# RL6845_IP_SVD register map
Vendor: Realtek
IP svd file
Registers are 32-bit, read-write, reset 0x0 unless marked. A register's access mark holds for its fields unless they carry their own. Offsets are from the block's base; lines under a group give offsets from that group; [hi:lo] are bit positions; {n}, {i} and the like mark numbered series; 'fields as' and 'values as' point back to an identical list; <NAME> marks a mode.

## Memory map
0x40000000 PAGE0 size 0x100
0x40000000 PAGE1 size 0x1200
0x40000000 PAGE2 size 0x300
0x40000000 PAGE3 size 0x1314
0x40000000 PAGE4 size 0x1488
0x40000000 PAGE5 size 0x15A4
0x40000000 PAGE6 size 0x1700
0x40000000 PAGE7 size 0x800
0x40100000 AES_REG size 0x101C
0x40108000 SHA_REG size 0x101C
0x40110000 GDMA0_REG size 0x400
0x40124000 SPI0_REG size 0xB0C
0x40125000 SPI1_REG size 0xB0C
0x40126000 PSRAM_PHY_REG size 0xFC
0x40127000 PSRAM_REG size 0x1D4
0x40128000 SPI_FLASH_CTRL size 0x1D4
0x40129000 QSPI_REG size 0x1D4
0x4012A000 SPORT0_REG size 0x984
0x4012B000 SPORT1_REG size 0x984
0x41000000 OTPC_REG size 0x744
0x41008000 LP_AON size 0x100
0x41008100 LDO size 0x80
0x41008180 SWR size 0x80
0x41008200 LP_SYS size 0x100
0x41008300 PMC size 0x88
0x41008400 XTAL size 0x3C
0x41008440 PLL size 0x40
0x41008480 WLAFE size 0x40
0x41008600 MEMX size 0x200
0x41008800 PINMUX_REG size 0x200
0x41008A00 RTC size 0x2C
0x41008C00 IWDG_REG size 0x14
0x41008D00 WDG0_REG size 0x14
0x41008D80 WDG2_REG size 0x14
0x41009000 SDM_REG size 0x24
0x4100C000 UART0_REG size 0x64
0x4100D000 UART1_REG size 0x64
0x4100E000 UART2_REG size 0x64
0x4100F000 UARTLOG_REG size 0xF4
0x41010000 GPIO_REG size 0x100
0x41011000 ADC_REG size 0xBC
0x41011800 CMP_REG size 0x58
0x41012000 CTC_REG size 0x214
0x41013000 KSCAN_REG size 0x5C
0x41014000 IPC0_REG size 0x1C
0x41014080 IPC1_REG size 0x1C
0x41015000 DEBUGTIMER_REG size 0x18
0x41016000 PMC_TIMER_REG size 0x34
{0x41017000+0x200*n} TIMER{n}_REG size 0x88 (n=0..7)
0x41100000 TIMER8_REG size 0x88
0x41100200 TIMER9_REG size 0x88
0x41100400 TIMER10_REG size 0x88
0x41100600 TIMER11_REG size 0x88
0x41101000 TRNG_REG size 0x200
0x41102000 RXI300_REG size 0x1140
0x41104000 RSIP_REG size 0x300
0x41105000 LEDC_REG size 0xF8
0x41106000 AUDIO_REG size 0x82C
0x41107000 IR_REG size 0x34
0x41108000 I2C0_REG size 0x104
0x4110A000 I2C1_REG size 0x104
0x51008D40 WDG1_REG_S size 0x14
0x51102200 MPC1_S size 0x1140
0x51102300 MPC2_S size 0x1140
0x51102400 PPC_S size 0x1140

## IPC0_REG
Base 0x41014000
Same registers: IPC1_REG 0x41014080
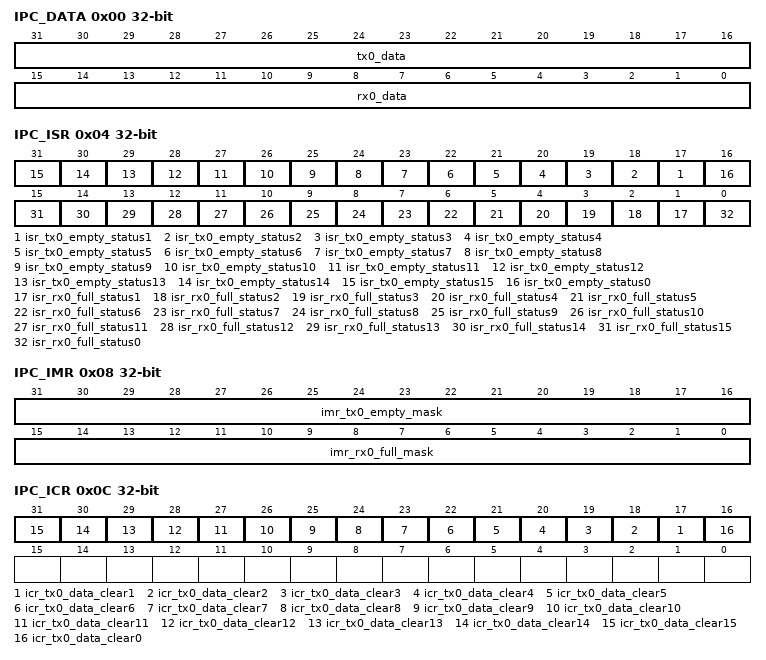
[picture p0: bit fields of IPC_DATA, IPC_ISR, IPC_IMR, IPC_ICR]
0x00 IPC_DATA access per field — Tx_Rx Register
  [31:16] tx0_data rw — After preparing descriptor, data and corresponding memory. 1: Writing 1 to the Tx data register (tx0_data) channel x bit, and the data will be mapped to the CPU0's RX data register (rx0_data) channel x bit. And the corresponding Rx full status bit in REG_ISR_CPU0 will be set. 0: Writing 0 has no effect. If the corresponding Rx full status bit in REG_ISR_CPU0 (e.g. isr_rx0_full_status6) is cleared, the corresponding bit in tx0_data will be cleaned automatically.
  [15:0] rx0_data ro — Rx data automatically maps data from tx0_data of CPU0
0x04 IPC_ISR ro — Interrupt Empty Full Status Register
  [n+16] isr_tx0_empty_status{n} (n=1..15) — Refer to the description of isr_tx0_empty_status0
  [16] isr_tx0_empty_status0 — Tx channel 0 empty interrupt status of CPU1 transmit to CPU0. If the corresponding Rx full status bit in REG_ISR_CPU0 (e.g. isr_rx0_full_status0) is cleared, the corresponding Tx empty status bit will be set automatically. It will be cleared by software writing 1.
  [n] isr_rx0_full_status{n} (n=1..15) — Refer to the description of isr_rx0_full_status0
  [0] isr_rx0_full_status0 — Rx channel 0 full interrupt status of CPU1. The corresponding Rx full status bit will be set by CPU0's Tx data register (tx0_data) channel 0. It will be cleared by software writing 1.
0x08 IPC_IMR — Interrupt Empty Full Mask Register
  [31:16] imr_tx0_empty_mask — 0: Mask Tx Channel x empty interrupt of CPU1 transmit to CPU0 1: Unmask Tx Channel x empty interrupt of CPU1 transmit to CPU0
  [15:0] imr_rx0_full_mask — 0: Mask Rx Channel x full interrupt of CPU1 received from CPU0 1: Unmask Rx Channel x full interrupt of CPU1 received from CPU0
0x0C IPC_ICR access per field — Clear Tx Register
  [n+16] icr_tx0_data_clear{n} ro (n=1..15) — Refer to the description of icr_tx0_data_clear0
  [16] icr_tx0_data_clear0 ro — 0: Writing 0 has no effect. 1: Clear the Tx data register (tx0_data) channel 0 bit.
0x10 IPC_SEM_0 ro
  [31:0] sem_0_data — Used to indicate who owns this semaphore .
0x14 IPC_SEM_1 ro
  [31:0] sem_1_data — Used to indicate who owns this semaphore .
0x18 IPC_DUMMY — Dummy Register
  [15:0] dummy

## Notices in the file
Copyright (C) 2012-2025 Realsil Limited. All rights reserved.
